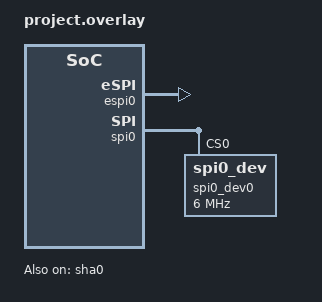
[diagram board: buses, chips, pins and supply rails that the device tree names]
/* Copyright 2025 The ChromiumOS Authors
 * Use of this source code is governed by a BSD-style license that can be
 * found in the LICENSE file.
 */

/* moonstone program common DTS includes */

#include <cros/integrated_fwid.dtsi>

/* moonstone project DTS includes */
#include "fan.dtsi"
#include "gpios.dtsi"
#include "i2c.dtsi"
#include "interrupts.dtsi"
#include "keyboard.dtsi"
#include "temp_sensors.dtsi"
#include "usb_typec.dtsi"

#include "../kinmen/adc.dtsi"
#include "../kinmen/binman.dtsi"
#include "../kinmen/console.dtsi"
#include "../kinmen/hibernate.dtsi"
#include "../kinmen/led_pins.dtsi"
#include "../kinmen/led_policy.dtsi"
#include "../kinmen/power_signals.dtsi"
#include "../kinmen/pwm.dtsi"
#include "../kinmen/usba.dtsi"
#include <moonstone/overlay.dtsi>

#include <cros/cbi_ufsc_std_schema.dtsi>
#include <cros/cbi_ufsc_oem_schema.dtsi>
#include "moonstone_ec_ufsc.dtsi"

/ {
	batteries {
		default_battery: atl-ap25aap {
			compatible = "atl,ap25aap", "battery-smart";
		};
		smp-ap25a7p {
			compatible = "smp,ap25a7p", "battery-smart";
		};
	};
};

/* AP interface */
&espi0 {
	status = "okay";
};

&sha0 {
	status = "okay";
};

&spi0 {
	status = "okay";
	pinctrl-0 = <&spi_ssce0_default &spi_smosi_default>;
	pinctrl-names = "default";

	spi0_dev0: spi0_dev@0 {
		reg = <0>;
		chain-length = <4>;
		reset-delay = <200>;
		spi-max-frequency = <6000000>;
		bits-per-symbol = <8>;
		spi-one-frame = <0xF8>;
		spi-zero-frame = <0xC0>;
	};
};
